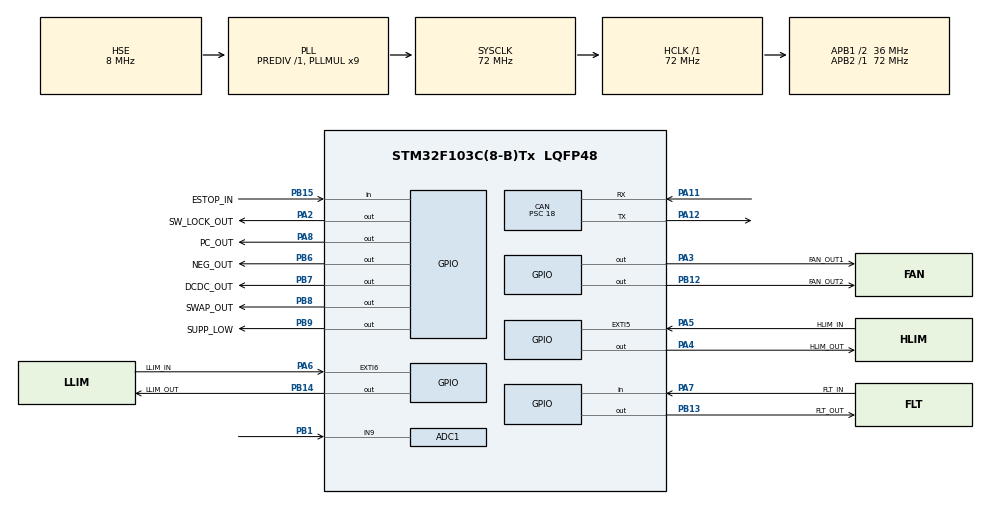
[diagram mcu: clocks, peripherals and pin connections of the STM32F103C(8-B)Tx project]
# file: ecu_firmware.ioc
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ADC1.Channel-0\#ChannelRegularConversion=ADC_CHANNEL_9
ADC1.ContinuousConvMode=ENABLE
ADC1.EnableInjectedConversion=DISABLE
ADC1.EnableRegularConversion=ENABLE
ADC1.ExternalTrigConv=ADC_EXTERNALTRIGCONV_T3_TRGO
ADC1.NbrOfConversionFlag=1
ADC1.Rank-0\#ChannelRegularConversion=1
ADC1.SamplingTime-0\#ChannelRegularConversion=ADC_SAMPLETIME_1CYCLE_5
ADC1.master=1
CAN.BS1=CAN_BS1_12TQ
CAN.BS2=CAN_BS2_3TQ
CAN.CalculateBaudRate=125000
CAN.CalculateTimeBit=8000.00
CAN.CalculateTimeQuantum=500.0
CAN.Prescaler=18
Dma.ADC1.0.Direction=DMA_PERIPH_TO_MEMORY
Dma.ADC1.0.Instance=DMA1_Channel1
Dma.ADC1.0.MemDataAlignment=DMA_MDATAALIGN_HALFWORD
Dma.ADC1.0.MemInc=DMA_MINC_ENABLE
Dma.ADC1.0.Mode=DMA_CIRCULAR
Dma.ADC1.0.PeriphDataAlignment=DMA_PDATAALIGN_HALFWORD
Dma.ADC1.0.PeriphInc=DMA_PINC_DISABLE
Dma.ADC1.0.Priority=DMA_PRIORITY_LOW
Dma.Request0=ADC1
Mcu.Family=STM32F1
Mcu.Name=STM32F103C(8-B)Tx
Mcu.Package=LQFP48
NVIC.PriorityGroup=NVIC_PRIORITYGROUP_1
PA11.Mode=CAN_Activate
PA11.Signal=CAN_RX
PA12.Mode=CAN_Activate
PA12.Signal=CAN_TX
PA13.Mode=Serial_Wire
PA13.Signal=SYS_JTMS-SWDIO
PA14.Mode=Serial_Wire
PA14.Signal=SYS_JTCK-SWCLK
PA2.GPIO_Label=SW_LOCK_OUT
PA2.GPIO_Speed=GPIO_SPEED_FREQ_HIGH
PA2.Signal=GPIO_Output
PA3.GPIO_Label=FAN_OUT1
PA3.GPIO_Speed=GPIO_SPEED_FREQ_HIGH
PA3.Signal=GPIO_Output
PA4.GPIO_Label=HLIM_OUT
PA4.GPIO_Speed=GPIO_SPEED_FREQ_HIGH
PA4.Signal=GPIO_Output
PA5.GPIO_Label=HLIM_IN
PA5.GPIO_ModeDefaultEXTI=GPIO_MODE_IT_RISING
PA5.Signal=GPXTI5
PA6.GPIO_Label=LLIM_IN
PA6.Signal=GPXTI6
PA7.GPIO_Label=FLT_IN
PA7.Signal=GPIO_Input
PA8.GPIO_Label=PC_OUT
PA8.GPIO_Speed=GPIO_SPEED_FREQ_HIGH
PA8.Signal=GPIO_Output
PB1.Signal=ADCx_IN9
PB12.GPIO_Label=FAN_OUT2
PB12.GPIO_Speed=GPIO_SPEED_FREQ_HIGH
PB12.Signal=GPIO_Output
PB13.GPIO_Label=FLT_OUT
PB13.GPIO_Speed=GPIO_SPEED_FREQ_HIGH
PB13.Signal=GPIO_Output
PB14.GPIO_Label=LLIM_OUT
PB14.GPIO_Speed=GPIO_SPEED_FREQ_HIGH
PB14.Signal=GPIO_Output
PB15.GPIO_Label=ESTOP_IN
PB15.Signal=GPIO_Input
PB6.GPIO_Label=NEG_OUT
PB6.GPIO_Speed=GPIO_SPEED_FREQ_HIGH
PB6.Signal=GPIO_Output
PB7.GPIO_Label=DCDC_OUT
PB7.GPIO_Speed=GPIO_SPEED_FREQ_HIGH
PB7.Signal=GPIO_Output
PB8.GPIO_Label=SWAP_OUT
PB8.GPIO_Speed=GPIO_SPEED_FREQ_HIGH
PB8.Signal=GPIO_Output
PB9.GPIO_Label=SUPP_LOW
PB9.GPIO_Speed=GPIO_SPEED_FREQ_HIGH
PB9.Signal=GPIO_Output
PD0-OSC_IN.Mode=HSE-External-Oscillator
PD0-OSC_IN.Signal=RCC_OSC_IN
PD1-OSC_OUT.Mode=HSE-External-Oscillator
PD1-OSC_OUT.Signal=RCC_OSC_OUT
ProjectManager.HeapSize=0x200
ProjectManager.StackSize=0x400
ProjectManager.TargetToolchain=STM32CubeIDE
RCC.ADCPresc=RCC_ADCPCLK2_DIV6
RCC.AHBFreq_Value=72000000
RCC.APB1CLKDivider=RCC_HCLK_DIV2
RCC.APB1Freq_Value=36000000
RCC.APB1TimFreq_Value=72000000
RCC.APB2Freq_Value=72000000
RCC.APB2TimFreq_Value=72000000
RCC.EnbaleCSS=true
RCC.HCLKFreq_Value=72000000
RCC.PLLMUL=RCC_PLL_MUL9
RCC.PLLSourceVirtual=RCC_PLLSOURCE_HSE
RCC.SYSCLKFreq_VALUE=72000000
RCC.SYSCLKSource=RCC_SYSCLKSOURCE_PLLCLK
RCC.USBFreq_Value=72000000
SH.ADCx_IN9.0=ADC1_IN9,IN9
TIM3.AutoReloadPreload=TIM_AUTORELOAD_PRELOAD_DISABLE
TIM3.Period=10000
TIM3.Prescaler=72
TIM3.TIM_MasterOutputTrigger=TIM_TRGO_UPDATE
TIM3.TIM_MasterSlaveMode=TIM_MASTERSLAVEMODE_ENABLE
VP_TIM3_VS_ClockSourceINT.Mode=Internal
board=custom

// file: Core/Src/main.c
/* USER CODE BEGIN Header */
/**
  ******************************************************************************
  * @file           : main.c
  * @brief          : Main program body
  ******************************************************************************
  * @attention
  *
  * <h2><center>&copy; Copyright (c) 2021 STMicroelectronics.
  * All rights reserved.</center></h2>
  *
  * This software component is licensed by ST under BSD 3-Clause license,
  * the "License"; You may not use this file except in compliance with the
  * License. You may obtain a copy of the License at:
  *                        opensource.org/licenses/BSD-3-Clause
  *
  ******************************************************************************
  */
/* USER CODE END Header */
#include "main.h"

ADC_HandleTypeDef hadc1;
DMA_HandleTypeDef hdma_adc1;

CAN_HandleTypeDef hcan;

TIM_HandleTypeDef htim3;

void SystemClock_Config(void);
static void MX_GPIO_Init(void);
static void MX_DMA_Init(void);
static void MX_ADC1_Init(void);
static void MX_CAN_Init(void);
static void MX_TIM3_Init(void);

int main(void)
{

  /* MCU Configuration--------------------------------------------------------*/

  /* Reset of all peripherals, Initializes the Flash interface and the Systick. */
  HAL_Init();

  HAL_DBGMCU_EnableDBGStandbyMode();
  HAL_DBGMCU_EnableDBGStopMode();

  /* Configure the system clock */
  SystemClock_Config();

  /* Initialize all configured peripherals */
  MX_GPIO_Init();
  MX_DMA_Init();
  MX_ADC1_Init();
  MX_CAN_Init();
  MX_TIM3_Init();
  /* USER CODE BEGIN 2 */

  //initialize sate machine
  SM_Init();

  /* USER CODE END 2 */

  /* Infinite loop */
  while (1)
  {

  }
}

void SystemClock_Config(void)
{
  RCC_OscInitTypeDef RCC_OscInitStruct = {0};
  RCC_ClkInitTypeDef RCC_ClkInitStruct = {0};
  RCC_PeriphCLKInitTypeDef PeriphClkInit = {0};

  /** Initializes the RCC Oscillators according to the specified parameters
  * in the RCC_OscInitTypeDef structure.
  */
  RCC_OscInitStruct.OscillatorType = RCC_OSCILLATORTYPE_HSE;
  RCC_OscInitStruct.HSEState = RCC_HSE_ON;
  RCC_OscInitStruct.HSEPredivValue = RCC_HSE_PREDIV_DIV1;
  RCC_OscInitStruct.HSIState = RCC_HSI_ON;
  RCC_OscInitStruct.PLL.PLLState = RCC_PLL_ON;
  RCC_OscInitStruct.PLL.PLLSource = RCC_PLLSOURCE_HSE;
  RCC_OscInitStruct.PLL.PLLMUL = RCC_PLL_MUL9;
  if (HAL_RCC_OscConfig(&RCC_OscInitStruct) != HAL_OK)
  {
    Error_Handler();
  }
  /** Initializes the CPU, AHB and APB buses clocks
  */
  RCC_ClkInitStruct.ClockType = RCC_CLOCKTYPE_HCLK|RCC_CLOCKTYPE_SYSCLK
                              |RCC_CLOCKTYPE_PCLK1|RCC_CLOCKTYPE_PCLK2;
  RCC_ClkInitStruct.SYSCLKSource = RCC_SYSCLKSOURCE_PLLCLK;
  RCC_ClkInitStruct.AHBCLKDivider = RCC_SYSCLK_DIV1;
  RCC_ClkInitStruct.APB1CLKDivider = RCC_HCLK_DIV2;
  RCC_ClkInitStruct.APB2CLKDivider = RCC_HCLK_DIV1;

  if (HAL_RCC_ClockConfig(&RCC_ClkInitStruct, FLASH_LATENCY_2) != HAL_OK)
  {
    Error_Handler();
  }
  PeriphClkInit.PeriphClockSelection = RCC_PERIPHCLK_ADC;
  PeriphClkInit.AdcClockSelection = RCC_ADCPCLK2_DIV6;
  if (HAL_RCCEx_PeriphCLKConfig(&PeriphClkInit) != HAL_OK)
  {
    Error_Handler();
  }
  /** Enables the Clock Security System
  */
  HAL_RCC_EnableCSS();
}

static void MX_ADC1_Init(void)
{

  ADC_ChannelConfTypeDef sConfig = {0};

  /** Common config
  */
  hadc1.Instance = ADC1;
  hadc1.Init.ScanConvMode = ADC_SCAN_DISABLE;
  hadc1.Init.ContinuousConvMode = ENABLE;
  hadc1.Init.DiscontinuousConvMode = DISABLE;
  hadc1.Init.ExternalTrigConv = ADC_EXTERNALTRIGCONV_T3_TRGO;
  hadc1.Init.DataAlign = ADC_DATAALIGN_RIGHT;
  hadc1.Init.NbrOfConversion = 1;
  if (HAL_ADC_Init(&hadc1) != HAL_OK)
  {
    Error_Handler();
  }
  /** Configure Regular Channel
  */
  sConfig.Channel = ADC_CHANNEL_9;
  sConfig.Rank = ADC_REGULAR_RANK_1;
  sConfig.SamplingTime = ADC_SAMPLETIME_1CYCLE_5;
  if (HAL_ADC_ConfigChannel(&hadc1, &sConfig) != HAL_OK)
  {
    Error_Handler();
  }

}

static void MX_CAN_Init(void)
{

  hcan.Instance = CAN1;
  hcan.Init.Prescaler = 18;
  hcan.Init.Mode = CAN_MODE_NORMAL;
  hcan.Init.SyncJumpWidth = CAN_SJW_1TQ;
  hcan.Init.TimeSeg1 = CAN_BS1_12TQ;
  hcan.Init.TimeSeg2 = CAN_BS2_3TQ;
  hcan.Init.TimeTriggeredMode = DISABLE;
  hcan.Init.AutoBusOff = DISABLE;
  hcan.Init.AutoWakeUp = DISABLE;
  hcan.Init.AutoRetransmission = DISABLE;
  hcan.Init.ReceiveFifoLocked = DISABLE;
  hcan.Init.TransmitFifoPriority = DISABLE;
  if (HAL_CAN_Init(&hcan) != HAL_OK)
  {
    Error_Handler();
  }

}

static void MX_TIM3_Init(void)
{

  TIM_ClockConfigTypeDef sClockSourceConfig = {0};
  TIM_MasterConfigTypeDef sMasterConfig = {0};

  htim3.Instance = TIM3;
  htim3.Init.Prescaler = 72;
  htim3.Init.CounterMode = TIM_COUNTERMODE_UP;
  htim3.Init.Period = 10000;
  htim3.Init.ClockDivision = TIM_CLOCKDIVISION_DIV1;
  htim3.Init.AutoReloadPreload = TIM_AUTORELOAD_PRELOAD_DISABLE;
  if (HAL_TIM_Base_Init(&htim3) != HAL_OK)
  {
    Error_Handler();
  }
  sClockSourceConfig.ClockSource = TIM_CLOCKSOURCE_INTERNAL;
  if (HAL_TIM_ConfigClockSource(&htim3, &sClockSourceConfig) != HAL_OK)
  {
    Error_Handler();
  }
  sMasterConfig.MasterOutputTrigger = TIM_TRGO_UPDATE;
  sMasterConfig.MasterSlaveMode = TIM_MASTERSLAVEMODE_ENABLE;
  if (HAL_TIMEx_MasterConfigSynchronization(&htim3, &sMasterConfig) != HAL_OK)
  {
    Error_Handler();
  }

}

static void MX_DMA_Init(void)
{

  /* DMA controller clock enable */
  __HAL_RCC_DMA1_CLK_ENABLE();

}

static void MX_GPIO_Init(void)
{
  GPIO_InitTypeDef GPIO_InitStruct = {0};

  /* GPIO Ports Clock Enable */
  __HAL_RCC_GPIOD_CLK_ENABLE();
  __HAL_RCC_GPIOA_CLK_ENABLE();
  __HAL_RCC_GPIOB_CLK_ENABLE();

  /*Configure GPIO pin Output Level */
  HAL_GPIO_WritePin(GPIOA, SW_LOCK_OUT_Pin|FAN_OUT1_Pin|HLIM_OUT_Pin|PC_OUT_Pin, GPIO_PIN_RESET);

  /*Configure GPIO pin Output Level */
  HAL_GPIO_WritePin(GPIOB, FAN_OUT2_Pin|FLT_OUT_Pin|LLIM_OUT_Pin|NEG_OUT_Pin
                          |DCDC_OUT_Pin|SWAP_OUT_Pin|SUPP_LOW_Pin, GPIO_PIN_RESET);

  /*Configure GPIO pins : SW_LOCK_OUT_Pin FAN_OUT1_Pin HLIM_OUT_Pin PC_OUT_Pin */
  GPIO_InitStruct.Pin = SW_LOCK_OUT_Pin|FAN_OUT1_Pin|HLIM_OUT_Pin|PC_OUT_Pin;
  GPIO_InitStruct.Mode = GPIO_MODE_OUTPUT_PP;
  GPIO_InitStruct.Pull = GPIO_NOPULL;
  GPIO_InitStruct.Speed = GPIO_SPEED_FREQ_HIGH;
  HAL_GPIO_Init(GPIOA, &GPIO_InitStruct);

  /*Configure GPIO pins : HLIM_IN_Pin LLIM_IN_Pin */
  GPIO_InitStruct.Pin = HLIM_IN_Pin|LLIM_IN_Pin;
  GPIO_InitStruct.Mode = GPIO_MODE_IT_RISING;
  GPIO_InitStruct.Pull = GPIO_NOPULL;
  HAL_GPIO_Init(GPIOA, &GPIO_InitStruct);

  /*Configure GPIO pin : FLT_IN_Pin */
  GPIO_InitStruct.Pin = FLT_IN_Pin;
  GPIO_InitStruct.Mode = GPIO_MODE_INPUT;
  GPIO_InitStruct.Pull = GPIO_NOPULL;
  HAL_GPIO_Init(FLT_IN_GPIO_Port, &GPIO_InitStruct);

  /*Configure GPIO pins : FAN_OUT2_Pin FLT_OUT_Pin LLIM_OUT_Pin NEG_OUT_Pin
                           DCDC_OUT_Pin SWAP_OUT_Pin SUPP_LOW_Pin */
  GPIO_InitStruct.Pin = FAN_OUT2_Pin|FLT_OUT_Pin|LLIM_OUT_Pin|NEG_OUT_Pin
                          |DCDC_OUT_Pin|SWAP_OUT_Pin|SUPP_LOW_Pin;
  GPIO_InitStruct.Mode = GPIO_MODE_OUTPUT_PP;
  GPIO_InitStruct.Pull = GPIO_NOPULL;
  GPIO_InitStruct.Speed = GPIO_SPEED_FREQ_HIGH;
  HAL_GPIO_Init(GPIOB, &GPIO_InitStruct);

  /*Configure GPIO pin : ESTOP_IN_Pin */
  GPIO_InitStruct.Pin = ESTOP_IN_Pin;
  GPIO_InitStruct.Mode = GPIO_MODE_INPUT;
  GPIO_InitStruct.Pull = GPIO_NOPULL;
  HAL_GPIO_Init(ESTOP_IN_GPIO_Port, &GPIO_InitStruct);

}

void Error_Handler(void)
{
  __disable_irq();
  while (1)
  {
  }
}

/************************ (C) COPYRIGHT STMicroelectronics *****END OF FILE****/
